AUTOSAR XML (schema 4-2-2)
package /ComponentTypes
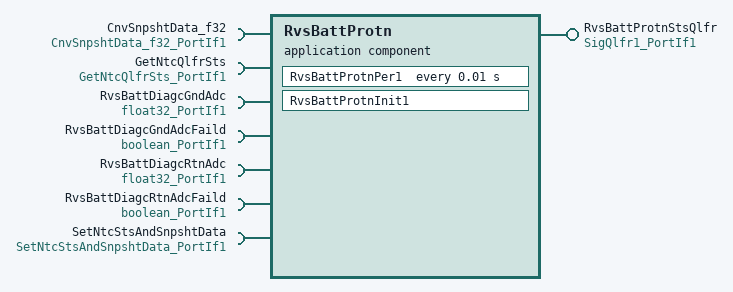
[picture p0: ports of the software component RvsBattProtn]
  application sw component type RvsBattProtn  # This module provides diagnostics of Reverse Battery Protection Module. Main task is to detect opened Reverese Protection MOSFET channel
    provide port RvsBattProtnStsQlfr: nonqueued-sender-com-spec{data-element=Val, init-value=0}, provided-interface=SigQlfr1_PortIf1
    7 x require port:
      CnvSnpshtData_f32: client-com-spec=Oper, required-interface=CnvSnpshtData_f32_PortIf1  # Convert a float data type to a uint32 data type
      GetNtcQlfrSts: client-com-spec=Oper, required-interface=GetNtcQlfrSts_PortIf1
      RvsBattDiagcGndAdc: nonqueued-receiver-com-spec{data-element=Val, filter=data-filter-type=ALWAYS, init-value=0}, required-interface=float32_PortIf1  # Reverse Battery Diagnostics Ground Adc measurement
      RvsBattDiagcGndAdcFaild: nonqueued-receiver-com-spec{data-element=Logl, filter=data-filter-type=ALWAYS, init-value=0}, required-interface=boolean_PortIf1  # Flag indicating correct ADC sampling of RvsBattDiagcGndAdc
      RvsBattDiagcRtnAdc: nonqueued-receiver-com-spec{data-element=Val, filter=data-filter-type=ALWAYS, init-value=0}, required-interface=float32_PortIf1  # Reverse Battery Diagnostics Return Adc measurement
      RvsBattDiagcRtnAdcFaild: nonqueued-receiver-com-spec{data-element=Logl, filter=data-filter-type=ALWAYS, init-value=0}, required-interface=boolean_PortIf1  # Flag indicating correct ADC sampling of RvsBattDiagcRtnAdc
      SetNtcStsAndSnpshtData: client-com-spec=Oper, required-interface=SetNtcStsAndSnpshtData_PortIf1  # Set NTC Status And Snapshot Data
    behavior RvsBattProtn_InternalBehavior
      init event RvsBattProtn_InitEvent: start-on-event=RvsBattProtnInit1
      timing event TMT_RvsBattProtnPer1: start-on-event=RvsBattProtnPer1, period=0.01
      port-api-options:
        enable-take-address=false, error-handling=NO-TRANSFORMER-ERROR-HANDLING, indirect-api=false, port=CnvSnpshtData_f32
        enable-take-address=false, error-handling=NO-TRANSFORMER-ERROR-HANDLING, indirect-api=false, port=GetNtcQlfrSts
        enable-take-address=false, error-handling=NO-TRANSFORMER-ERROR-HANDLING, indirect-api=false, port=RvsBattDiagcGndAdc
        enable-take-address=false, error-handling=NO-TRANSFORMER-ERROR-HANDLING, indirect-api=false, port=RvsBattDiagcGndAdcFaild
        enable-take-address=false, error-handling=NO-TRANSFORMER-ERROR-HANDLING, indirect-api=false, port=RvsBattDiagcRtnAdc
        enable-take-address=false, error-handling=NO-TRANSFORMER-ERROR-HANDLING, indirect-api=false, port=RvsBattDiagcRtnAdcFaild
        enable-take-address=false, error-handling=NO-TRANSFORMER-ERROR-HANDLING, indirect-api=false, port=RvsBattProtnStsQlfr
        enable-take-address=false, error-handling=NO-TRANSFORMER-ERROR-HANDLING, indirect-api=false, port=SetNtcStsAndSnpshtData
      runnable RvsBattProtnInit1
      runnable RvsBattProtnPer1
        data-receive-point-by-arguments:
          4 x access:
            REC_RvsBattDiagcGndAdc_Val: accessed-variable=RvsBattDiagcGndAdc.Val
            REC_RvsBattDiagcGndAdcFaild_Logl: accessed-variable=RvsBattDiagcGndAdcFaild.Logl
            REC_RvsBattDiagcRtnAdc_Val: accessed-variable=RvsBattDiagcRtnAdc.Val
            REC_RvsBattDiagcRtnAdcFaild_Logl: accessed-variable=RvsBattDiagcRtnAdcFaild.Logl
        data-send-points:
          access SEND_RvsBattProtnStsQlfr_Val: accessed-variable=RvsBattProtnStsQlfr.Val
        sync call SC_CnvSnpshtData_f32_Oper: operation=CnvSnpshtData_f32.Oper, timeout=0
        sync call SC_GetNtcQlfrSts_Oper: operation=GetNtcQlfrSts.Oper, timeout=0
        sync call SC_SetNtcStsAndSnpshtData_Oper: operation=SetNtcStsAndSnpshtData.Oper, timeout=0
  swc implementation RvsBattProtn_Implementation: behavior=RvsBattProtn_InternalBehavior
    code-descriptors:
      code Default: artifact-descriptors=autosar-engineering-object={short-label=Default, category=SWSRC}
